VERSION ""

NS_ :

BS_:

BU_: Vector__XXX

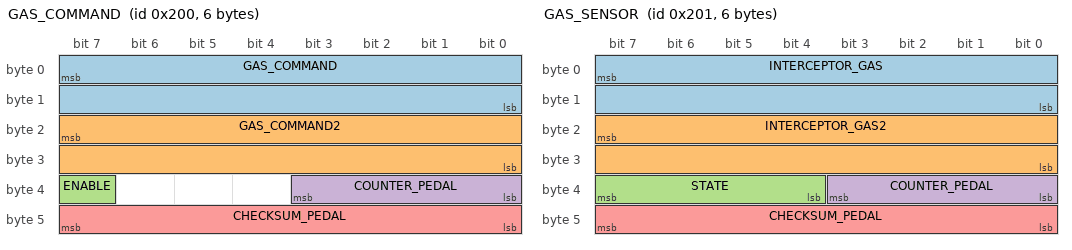
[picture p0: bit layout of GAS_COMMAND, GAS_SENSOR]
BO_ 512 GAS_COMMAND: 6 Vector__XXX
SG_ GAS_COMMAND : 7|16@0+ (0.253984064,-83.3) [0|1] "" Vector__XXX
SG_ GAS_COMMAND2 : 23|16@0+ (0.126992032,-83.3) [0|1] "" Vector__XXX
SG_ ENABLE : 39|1@0+ (1,0) [0|1] "" Vector__XXX
SG_ COUNTER_PEDAL : 35|4@0+ (1,0) [0|15] "" Vector__XXX
SG_ CHECKSUM_PEDAL : 47|8@0+ (1,0) [0|255] "" Vector__XXX

BO_ 513 GAS_SENSOR: 6 Vector__XXX
SG_ INTERCEPTOR_GAS : 7|16@0+ (1,0) [0|1] "" Vector__XXX
SG_ INTERCEPTOR_GAS2 : 23|16@0+ (1,0) [0|1] "" Vector__XXX
SG_ STATE : 39|4@0+ (1,0) [0|15] "" Vector__XXX
SG_ COUNTER_PEDAL : 35|4@0+ (1,0) [0|15] "" Vector__XXX
SG_ CHECKSUM_PEDAL : 47|8@0+ (1,0) [0|255] "" Vector__XXX

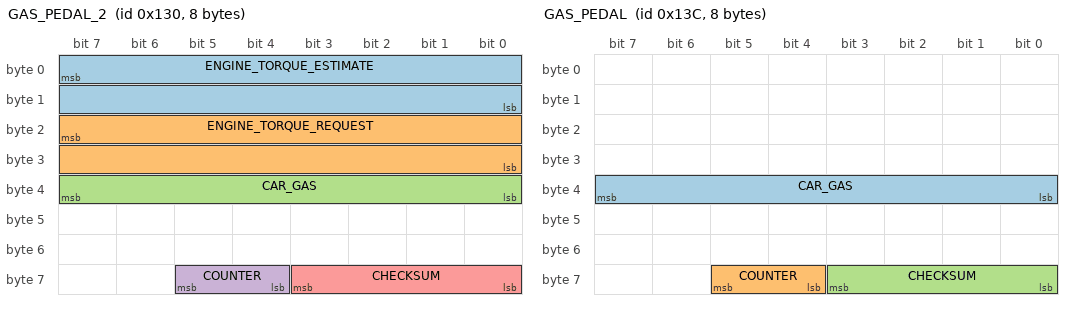
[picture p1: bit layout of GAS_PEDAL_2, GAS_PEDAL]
BO_ 304 GAS_PEDAL_2: 8 Vector__XXX
SG_ ENGINE_TORQUE_ESTIMATE : 7|16@0- (1,0) [-1000|1000] "Nm" Vector__XXX
SG_ ENGINE_TORQUE_REQUEST : 23|16@0- (1,0) [-1000|1000] "Nm" Vector__XXX
SG_ CAR_GAS : 39|8@0+ (1,0) [0|255] "" Vector__XXX
SG_ COUNTER : 61|2@0+ (1,0) [0|3] "" Vector__XXX
SG_ CHECKSUM : 59|4@0+ (1,0) [0|15] "" Vector__XXX

BO_ 316 GAS_PEDAL: 8 Vector__XXX
SG_ CAR_GAS : 39|8@0+ (1,0) [0|255] "" Vector__XXX
SG_ COUNTER : 61|2@0+ (1,0) [0|3] "" Vector__XXX
SG_ CHECKSUM : 59|4@0+ (1,0) [0|15] "" Vector__XXX

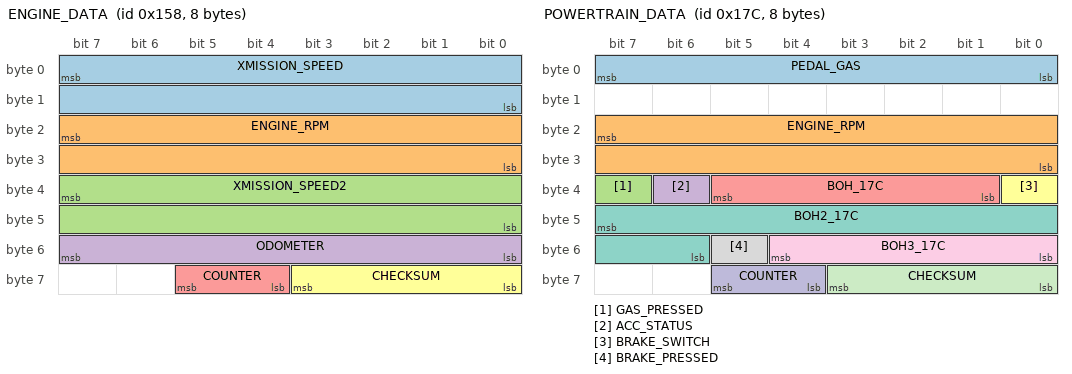
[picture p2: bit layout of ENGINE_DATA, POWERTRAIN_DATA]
BO_ 344 ENGINE_DATA: 8 Vector__XXX
SG_ XMISSION_SPEED : 7|16@0+ (0.01,0) [0|250] "kph" Vector__XXX
SG_ ENGINE_RPM : 23|16@0+ (1,0) [0|15000] "rpm" Vector__XXX
SG_ XMISSION_SPEED2 : 39|16@0+ (0.01,0) [0|250] "kph" Vector__XXX
SG_ ODOMETER : 55|8@0+ (10,0) [0|2550] "m" Vector__XXX
SG_ COUNTER : 61|2@0+ (1,0) [0|3] "" Vector__XXX
SG_ CHECKSUM : 59|4@0+ (1,0) [0|15] "" Vector__XXX

BO_ 380 POWERTRAIN_DATA: 8 Vector__XXX
SG_ PEDAL_GAS : 7|8@0+ (1,0) [0|255] "" Vector__XXX
SG_ ENGINE_RPM : 23|16@0+ (1,0) [0|15000] "rpm" Vector__XXX
SG_ GAS_PRESSED : 39|1@0+ (1,0) [0|1] "" Vector__XXX
SG_ ACC_STATUS : 38|1@0+ (1,0) [0|1] "" Vector__XXX
SG_ BOH_17C : 37|5@0+ (1,0) [0|1] "" Vector__XXX
SG_ BRAKE_SWITCH : 32|1@0+ (1,0) [0|1] "" Vector__XXX
SG_ BOH2_17C : 47|10@0+ (1,0) [0|1] "" Vector__XXX
SG_ BRAKE_PRESSED : 53|1@0+ (1,0) [0|1] "" Vector__XXX
SG_ BOH3_17C : 52|5@0+ (1,0) [0|1] "" Vector__XXX
SG_ COUNTER : 61|2@0+ (1,0) [0|3] "" Vector__XXX
SG_ CHECKSUM : 59|4@0+ (1,0) [0|15] "" Vector__XXX

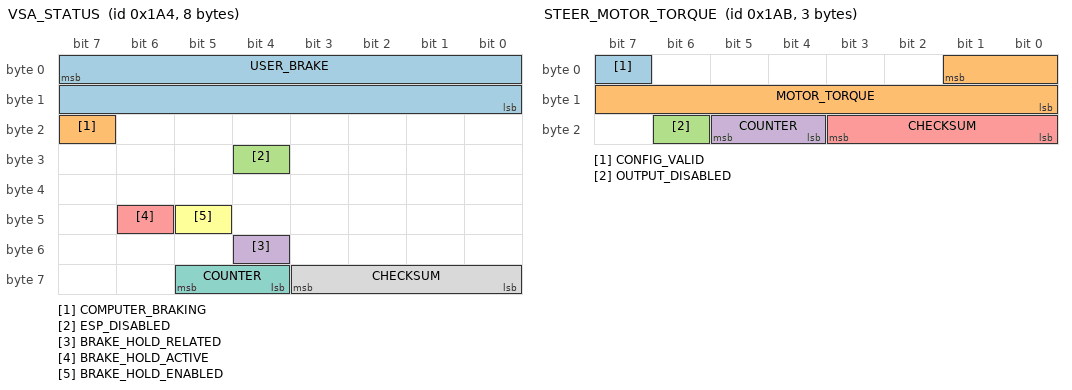
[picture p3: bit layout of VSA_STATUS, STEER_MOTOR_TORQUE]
BO_ 420 VSA_STATUS: 8 Vector__XXX
SG_ USER_BRAKE : 7|16@0+ (0.015625,-1.609375) [0|1000] "" Vector__XXX
SG_ COMPUTER_BRAKING : 23|1@0+ (1,0) [0|1] "" Vector__XXX
SG_ ESP_DISABLED : 28|1@0+ (1,0) [0|1] "" Vector__XXX
SG_ BRAKE_HOLD_RELATED : 52|1@0+ (1,0) [0|1] "" Vector__XXX
SG_ BRAKE_HOLD_ACTIVE : 46|1@0+ (1,0) [0|1] "" Vector__XXX
SG_ BRAKE_HOLD_ENABLED : 45|1@0+ (1,0) [0|1] "" Vector__XXX
SG_ COUNTER : 61|2@0+ (1,0) [0|3] "" Vector__XXX
SG_ CHECKSUM : 59|4@0+ (1,0) [0|15] "" Vector__XXX

BO_ 427 STEER_MOTOR_TORQUE: 3 Vector__XXX
SG_ CONFIG_VALID : 7|1@0+ (1,0) [0|1] "" Vector__XXX
SG_ MOTOR_TORQUE : 1|10@0+ (1,0) [0|256] "" Vector__XXX
SG_ OUTPUT_DISABLED : 22|1@0+ (1,0) [0|1] "" Vector__XXX
SG_ COUNTER : 21|2@0+ (1,0) [0|3] "" Vector__XXX
SG_ CHECKSUM : 19|4@0+ (1,0) [0|15] "" Vector__XXX

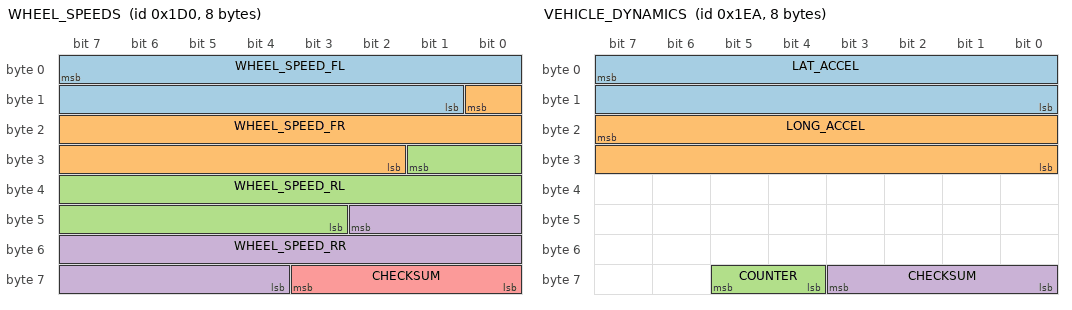
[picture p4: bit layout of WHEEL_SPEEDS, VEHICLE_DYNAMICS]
BO_ 464 WHEEL_SPEEDS: 8 Vector__XXX
SG_ WHEEL_SPEED_FL : 7|15@0+ (0.01,0) [0|250] "kph" Vector__XXX
SG_ WHEEL_SPEED_FR : 8|15@0+ (0.01,0) [0|250] "kph" Vector__XXX
SG_ WHEEL_SPEED_RL : 25|15@0+ (0.01,0) [0|250] "kph" Vector__XXX
SG_ WHEEL_SPEED_RR : 42|15@0+ (0.01,0) [0|250] "kph" Vector__XXX
SG_ CHECKSUM : 59|4@0+ (1,0) [0|3] "" Vector__XXX

BO_ 490 VEHICLE_DYNAMICS: 8 Vector__XXX
SG_ LAT_ACCEL : 7|16@0- (0.0015,0) [-20|20] "m/s2" Vector__XXX
SG_ LONG_ACCEL : 23|16@0- (0.0015,0) [-20|20] "m/s2" Vector__XXX
SG_ COUNTER : 61|2@0+ (1,0) [0|3] "" Vector__XXX
SG_ CHECKSUM : 59|4@0+ (1,0) [0|3] "" Vector__XXX

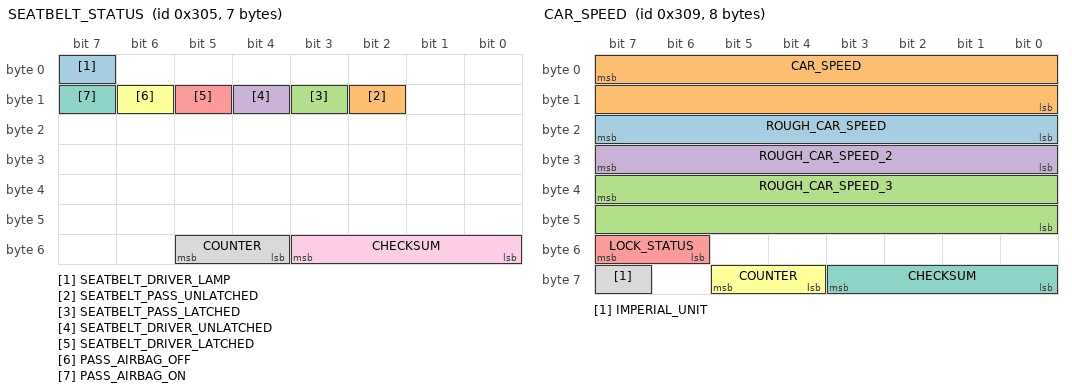
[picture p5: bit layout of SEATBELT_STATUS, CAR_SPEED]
BO_ 773 SEATBELT_STATUS: 7 Vector__XXX
SG_ SEATBELT_DRIVER_LAMP : 7|1@0+ (1,0) [0|1] "" Vector__XXX
SG_ SEATBELT_PASS_UNLATCHED : 10|1@0+ (1,0) [0|1] "" Vector__XXX
SG_ SEATBELT_PASS_LATCHED : 11|1@0+ (1,0) [0|1] "" Vector__XXX
SG_ SEATBELT_DRIVER_UNLATCHED : 12|1@0+ (1,0) [0|1] "" Vector__XXX
SG_ SEATBELT_DRIVER_LATCHED : 13|1@0+ (1,0) [0|1] "" Vector__XXX
SG_ PASS_AIRBAG_OFF : 14|1@0+ (1,0) [0|1] "" Vector__XXX
SG_ PASS_AIRBAG_ON : 15|1@0+ (1,0) [0|1] "" Vector__XXX
SG_ COUNTER : 53|2@0+ (1,0) [0|3] "" Vector__XXX
SG_ CHECKSUM : 51|4@0+ (1,0) [0|3] "" Vector__XXX

BO_ 777 CAR_SPEED: 8 Vector__XXX
SG_ ROUGH_CAR_SPEED : 23|8@0+ (1,0) [0|255] "mph" Vector__XXX
SG_ CAR_SPEED : 7|16@0+ (0.01,0) [0|655.35] "kph" Vector__XXX
SG_ ROUGH_CAR_SPEED_3 : 39|16@0+ (0.01,0) [0|655.35] "kph" Vector__XXX
SG_ ROUGH_CAR_SPEED_2 : 31|8@0+ (1,0) [0|255] "mph" Vector__XXX
SG_ LOCK_STATUS : 55|2@0+ (1,0) [0|3] "" Vector__XXX
SG_ COUNTER : 61|2@0+ (1,0) [0|3] "" Vector__XXX
SG_ CHECKSUM : 59|4@0+ (1,0) [0|15] "" Vector__XXX
SG_ IMPERIAL_UNIT : 63|1@0+ (1,0) [0|1] "" Vector__XXX

BO_ 780 ACC_HUD: 8 Vector__XXX
SG_ PCM_SPEED : 7|16@0+ (0.01,0) [0|250] "kph" Vector__XXX
SG_ PCM_GAS : 23|8@0+ (1,0) [0|127] "" Vector__XXX
SG_ CRUISE_SPEED : 31|8@0+ (1,0) [0|255] "kph" Vector__XXX
SG_ DTC_MODE : 39|1@0+ (1,0) [0|1] "" Vector__XXX
SG_ BOH : 38|1@0+ (1,0) [0|1] "" Vector__XXX
SG_ ACC_PROBLEM : 37|1@0+ (1,0) [0|1] "" Vector__XXX
SG_ FCM_OFF : 35|1@0+ (1,0) [0|1] "" Vector__XXX
SG_ FCM_OFF_2 : 36|1@0+ (1,0) [0|1] "" Vector__XXX
SG_ FCM_PROBLEM : 34|1@0+ (1,0) [0|1] "" Vector__XXX
SG_ RADAR_OBSTRUCTED : 33|1@0+ (1,0) [0|1] "" Vector__XXX
SG_ ENABLE_MINI_CAR : 32|1@0+ (1,0) [0|1] "" Vector__XXX
SG_ HUD_DISTANCE : 47|2@0+ (1,0) [0|3] "" Vector__XXX
SG_ HUD_LEAD : 45|2@0+ (1,0) [0|3] "" Vector__XXX
SG_ BOH_3 : 43|1@0+ (1,0) [0|1] "" Vector__XXX
SG_ BOH_4 : 42|1@0+ (1,0) [0|1] "" Vector__XXX
SG_ BOH_5 : 41|1@0+ (1,0) [0|1] "" Vector__XXX
SG_ CRUISE_CONTROL_LABEL : 40|1@0+ (1,0) [0|1] "" Vector__XXX
SG_ SET_ME_X01_2 : 55|1@0+ (1,0) [0|1] "" Vector__XXX
SG_ IMPERIAL_UNIT : 54|1@0+ (1,0) [0|1] "" Vector__XXX
SG_ ACC_ON : 52|1@0+ (1,0) [0|1] "" Vector__XXX
SG_ CHIME : 51|3@0+ (1,0) [0|1] "" Vector__XXX
SG_ SET_ME_X01 : 48|1@0+ (1,0) [0|1] "" Vector__XXX
SG_ ICONS : 63|2@0+ (1,0) [0|1] "" Vector__XXX
SG_ COUNTER : 61|2@0+ (1,0) [0|3] "" Vector__XXX
SG_ CHECKSUM : 59|4@0+ (1,0) [0|3] "" Vector__XXX

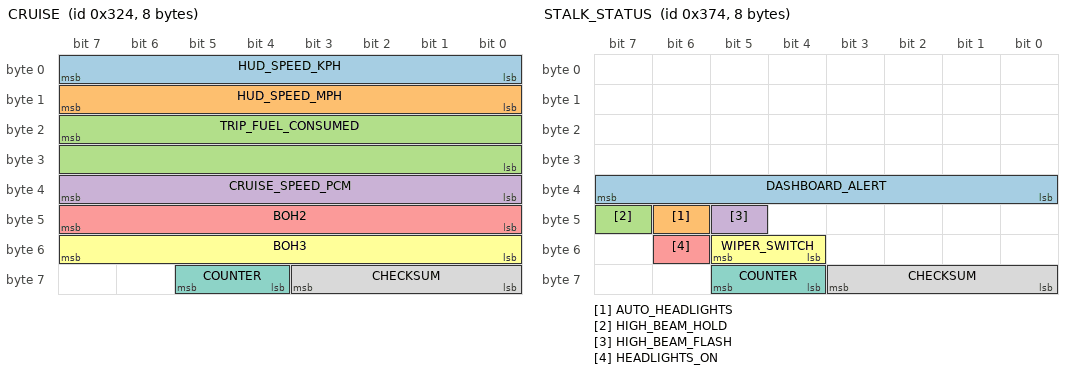
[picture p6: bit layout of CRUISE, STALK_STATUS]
BO_ 804 CRUISE: 8 Vector__XXX
SG_ HUD_SPEED_KPH : 7|8@0+ (1,0) [0|255] "kph" Vector__XXX
SG_ HUD_SPEED_MPH : 15|8@0+ (1,0) [0|255] "mph" Vector__XXX
SG_ TRIP_FUEL_CONSUMED : 23|16@0+ (1,0) [0|255] "" Vector__XXX
SG_ CRUISE_SPEED_PCM : 39|8@0+ (1,0) [0|255] "" Vector__XXX
SG_ BOH2 : 47|8@0- (1,0) [0|127] "" Vector__XXX
SG_ BOH3 : 55|8@0+ (1,0) [0|255] "" Vector__XXX
SG_ COUNTER : 61|2@0+ (1,0) [0|3] "" Vector__XXX
SG_ CHECKSUM : 59|4@0+ (1,0) [0|15] "" Vector__XXX

BO_ 884 STALK_STATUS: 8 Vector__XXX
SG_ DASHBOARD_ALERT : 39|8@0+ (1,0) [0|255] "" Vector__XXX
SG_ AUTO_HEADLIGHTS : 46|1@0+ (1,0) [0|1] "" Vector__XXX
SG_ HIGH_BEAM_HOLD : 47|1@0+ (1,0) [0|1] "" Vector__XXX
SG_ HIGH_BEAM_FLASH : 45|1@0+ (1,0) [0|1] "" Vector__XXX
SG_ HEADLIGHTS_ON : 54|1@0+ (1,0) [0|1] "" Vector__XXX
SG_ WIPER_SWITCH : 53|2@0+ (1,0) [0|3] "" Vector__XXX
SG_ COUNTER : 61|2@0+ (1,0) [0|3] "" Vector__XXX
SG_ CHECKSUM : 59|4@0+ (1,0) [0|15] "" Vector__XXX

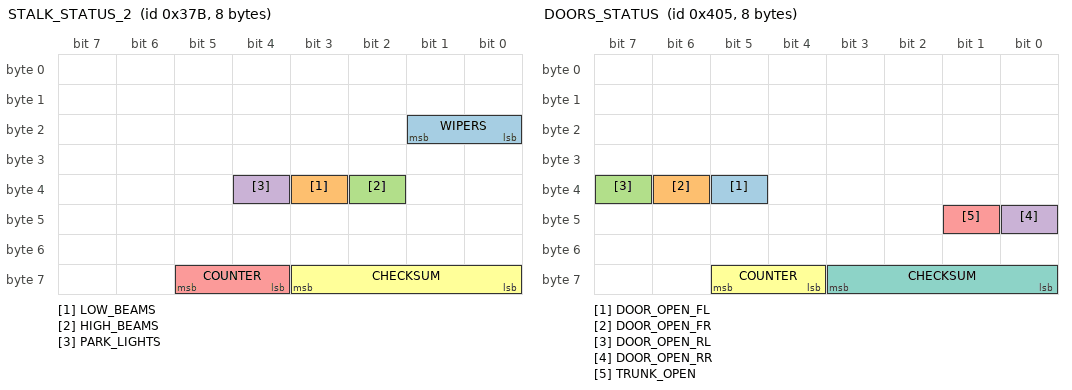
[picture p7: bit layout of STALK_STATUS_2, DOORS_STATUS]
BO_ 891 STALK_STATUS_2: 8 Vector__XXX
SG_ WIPERS : 17|2@0+ (1,0) [0|3] "" Vector__XXX
SG_ LOW_BEAMS : 35|1@0+ (1,0) [0|1] "" Vector__XXX
SG_ HIGH_BEAMS : 34|1@0+ (1,0) [0|1] "" Vector__XXX
SG_ PARK_LIGHTS : 36|1@0+ (1,0) [0|1] "" Vector__XXX
SG_ COUNTER : 61|2@0+ (1,0) [0|3] "" Vector__XXX
SG_ CHECKSUM : 59|4@0+ (1,0) [0|15] "" Vector__XXX

BO_ 1029 DOORS_STATUS: 8 Vector__XXX
SG_ DOOR_OPEN_FL : 37|1@0+ (1,0) [0|1] "" Vector__XXX
SG_ DOOR_OPEN_FR : 38|1@0+ (1,0) [0|1] "" Vector__XXX
SG_ DOOR_OPEN_RL : 39|1@0+ (1,0) [0|1] "" Vector__XXX
SG_ DOOR_OPEN_RR : 40|1@0+ (1,0) [0|1] "" Vector__XXX
SG_ TRUNK_OPEN : 41|1@0+ (1,0) [0|1] "" Vector__XXX
SG_ COUNTER : 61|2@0+ (1,0) [0|3] "" Vector__XXX
SG_ CHECKSUM : 59|4@0+ (1,0) [0|15] "" Vector__XXX

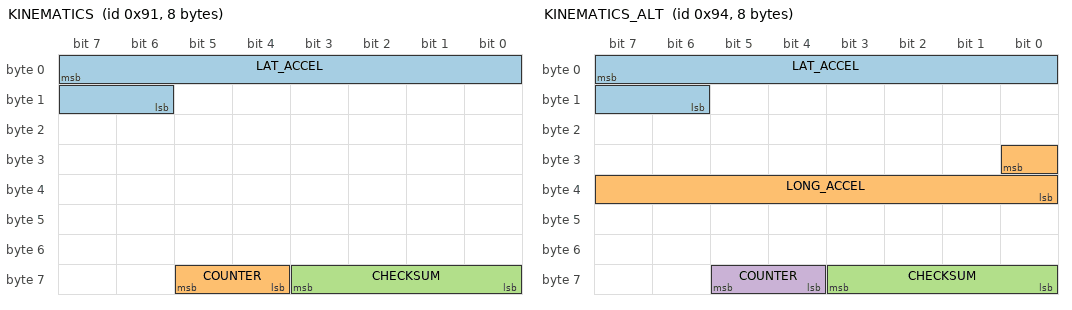
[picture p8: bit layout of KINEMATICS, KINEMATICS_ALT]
BO_ 145 KINEMATICS: 8 Vector__XXX
SG_ LAT_ACCEL : 7|10@0+ (0.02,-512) [-20|-491.54] "m/s2" Vector__XXX
SG_ COUNTER : 61|2@0+ (1,0) [0|3] "" Vector__XXX
SG_ CHECKSUM : 59|4@0+ (1,0) [0|3] "" Vector__XXX

BO_ 148 KINEMATICS_ALT: 8 Vector__XXX
SG_ LAT_ACCEL : 7|10@0+ (0.02,-512) [-20|-491.54] "m/s2" Vector__XXX
SG_ LONG_ACCEL : 24|9@0- (-0.02,0) [-5.1|5.12] "m/s2" Vector__XXX
SG_ CHECKSUM : 59|4@0+ (1,0) [0|3] "" Vector__XXX
SG_ COUNTER : 61|2@0+ (1,0) [0|3] "" Vector__XXX

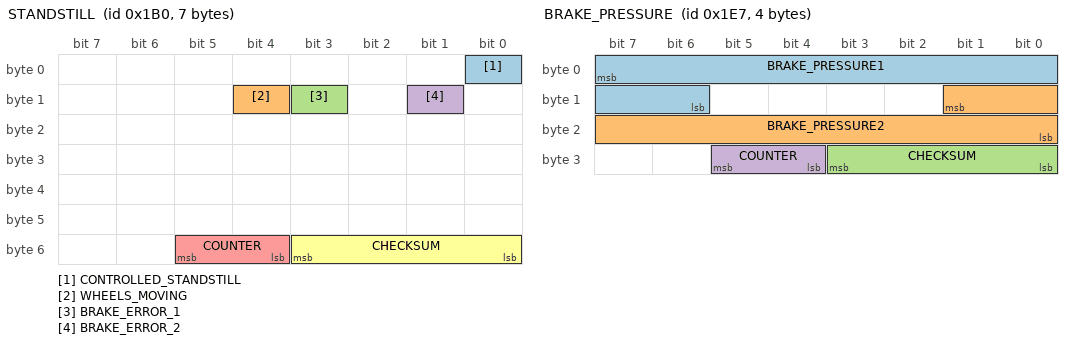
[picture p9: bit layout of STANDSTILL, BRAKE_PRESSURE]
BO_ 432 STANDSTILL: 7 Vector__XXX
SG_ CONTROLLED_STANDSTILL : 0|1@0+ (1,0) [0|1] "" Vector__XXX
SG_ WHEELS_MOVING : 12|1@0+ (1,0) [0|1] "" Vector__XXX
SG_ BRAKE_ERROR_1 : 11|1@0+ (1,0) [0|1] "" Vector__XXX
SG_ BRAKE_ERROR_2 : 9|1@0+ (1,0) [0|1] "" Vector__XXX
SG_ COUNTER : 53|2@0+ (1,0) [0|3] "" Vector__XXX
SG_ CHECKSUM : 51|4@0+ (1,0) [0|3] "" Vector__XXX

BO_ 487 BRAKE_PRESSURE: 4 Vector__XXX
SG_ BRAKE_PRESSURE1 : 7|10@0+ (0.015625,-103) [0|-87.015625] "" Vector__XXX
SG_ BRAKE_PRESSURE2 : 9|10@0+ (0.015625,-103) [0|-87.015625] "" Vector__XXX
SG_ CHECKSUM : 27|4@0+ (1,0) [0|15] "" Vector__XXX
SG_ COUNTER : 29|2@0+ (1,0) [0|3] "" Vector__XXX

BO_ 506 BRAKE_COMMAND: 8 Vector__XXX
SG_ COMPUTER_BRAKE : 7|10@0+ (1,0) [0|1] "" Vector__XXX
SG_ BRAKE_PUMP_REQUEST : 8|1@0+ (1,0) [0|1] "" Vector__XXX
SG_ BRAKE_PUMP_REQUEST_ALT : 11|1@0+ (1,0) [0|1] "" Vector__XXX
SG_ SET_ME_X00 : 23|3@0+ (1,0) [0|1] "" Vector__XXX
SG_ CRUISE_OVERRIDE : 20|1@0+ (1,0) [0|1] "" Vector__XXX
SG_ SET_ME_X00_2 : 19|1@0+ (1,0) [0|1] "" Vector__XXX
SG_ CRUISE_FAULT_CMD : 18|1@0+ (1,0) [0|1] "" Vector__XXX
SG_ CRUISE_CANCEL_CMD : 17|1@0+ (1,0) [0|1] "" Vector__XXX
SG_ COMPUTER_BRAKE_REQUEST : 16|1@0+ (1,0) [0|1] "" Vector__XXX
SG_ SET_ME_1 : 31|1@0+ (1,0) [0|1] "" Vector__XXX
SG_ AEB_REQ_1 : 29|1@0+ (1,0) [0|1] "" Vector__XXX
SG_ AEB_REQ_2 : 26|3@0+ (1,0) [0|7] "" Vector__XXX
SG_ BRAKE_LIGHTS : 39|1@0+ (1,0) [0|1] "" Vector__XXX
SG_ CRUISE_STATES : 38|7@0+ (1,0) [0|1] "" Vector__XXX
SG_ CHIME : 47|3@0+ (1,0) [0|7] "" Vector__XXX
SG_ SET_ME_X00_3 : 44|1@0+ (1,0) [0|1] "" Vector__XXX
SG_ FCW : 43|2@0+ (1,0) [0|3] "" Vector__XXX
SG_ AEB_STATUS : 41|2@0+ (1,0) [0|3] "" Vector__XXX
SG_ COMPUTER_BRAKE_ALT : 55|10@0+ (1,0) [0|1023] "" Vector__XXX
SG_ COUNTER : 61|2@0+ (1,0) [0|3] "" Vector__XXX
SG_ CHECKSUM : 59|4@0+ (1,0) [0|15] "" Vector__XXX

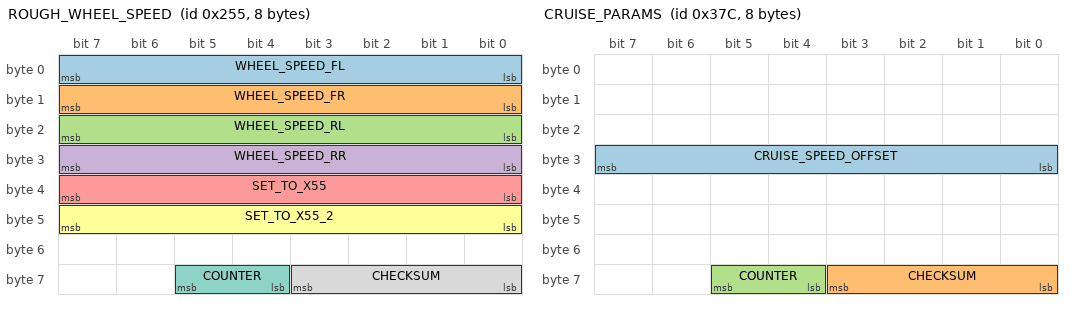
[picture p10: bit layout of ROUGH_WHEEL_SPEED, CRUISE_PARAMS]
BO_ 597 ROUGH_WHEEL_SPEED: 8 Vector__XXX
SG_ WHEEL_SPEED_FL : 7|8@0+ (1,0) [0|255] "mph" Vector__XXX
SG_ WHEEL_SPEED_FR : 15|8@0+ (1,0) [0|255] "mph" Vector__XXX
SG_ WHEEL_SPEED_RL : 23|8@0+ (1,0) [0|255] "mph" Vector__XXX
SG_ WHEEL_SPEED_RR : 31|8@0+ (1,0) [0|255] "mph" Vector__XXX
SG_ SET_TO_X55 : 39|8@0+ (1,0) [0|255] "" Vector__XXX
SG_ SET_TO_X55_2 : 47|8@0+ (1,0) [0|255] "" Vector__XXX
SG_ COUNTER : 61|2@0+ (1,0) [0|3] "" Vector__XXX
SG_ CHECKSUM : 59|4@0+ (1,0) [0|15] "" Vector__XXX

BO_ 829 LKAS_HUD: 5 Vector__XXX
SG_ CAM_TEMP_HIGH : 7|1@0+ (1,0) [0|1] "" Vector__XXX
SG_ SET_ME_X41 : 6|7@0+ (1,0) [0|127] "" Vector__XXX
SG_ BOH : 6|7@0+ (1,0) [0|127] "" Vector__XXX
SG_ DASHED_LANES : 14|1@0+ (1,0) [0|1] "" Vector__XXX
SG_ DTC : 13|1@0+ (1,0) [0|1] "" Vector__XXX
SG_ LKAS_PROBLEM : 12|1@0+ (1,0) [0|1] "" Vector__XXX
SG_ LKAS_OFF : 11|1@0+ (1,0) [0|1] "" Vector__XXX
SG_ SOLID_LANES : 10|1@0+ (1,0) [0|1] "" Vector__XXX
SG_ LDW_RIGHT : 9|1@0+ (1,0) [0|1] "" Vector__XXX
SG_ STEERING_REQUIRED : 8|1@0+ (1,0) [0|1] "" Vector__XXX
SG_ BOH_2 : 23|2@0+ (1,0) [0|3] "" Vector__XXX
SG_ LDW_PROBLEM : 21|1@0+ (1,0) [0|1] "" Vector__XXX
SG_ BEEP : 17|2@0+ (1,0) [0|1] "" Vector__XXX
SG_ LDW_ON : 28|1@0+ (1,0) [0|1] "" Vector__XXX
SG_ LDW_OFF : 27|1@0+ (1,0) [0|1] "" Vector__XXX
SG_ CLEAN_WINDSHIELD : 26|1@0+ (1,0) [0|1] "" Vector__XXX
SG_ SET_ME_X48 : 31|8@0+ (1,0) [0|255] "" Vector__XXX
SG_ COUNTER : 37|2@0+ (1,0) [0|3] "" Vector__XXX
SG_ CHECKSUM : 35|4@0+ (1,0) [0|15] "" Vector__XXX

BO_ 892 CRUISE_PARAMS: 8 Vector__XXX
SG_ CRUISE_SPEED_OFFSET : 31|8@0- (0.1,0) [-12.8|12.7] "kph" Vector__XXX
SG_ CHECKSUM : 59|4@0+ (1,0) [0|3] "" Vector__XXX
SG_ COUNTER : 61|2@0+ (1,0) [0|3] "" Vector__XXX

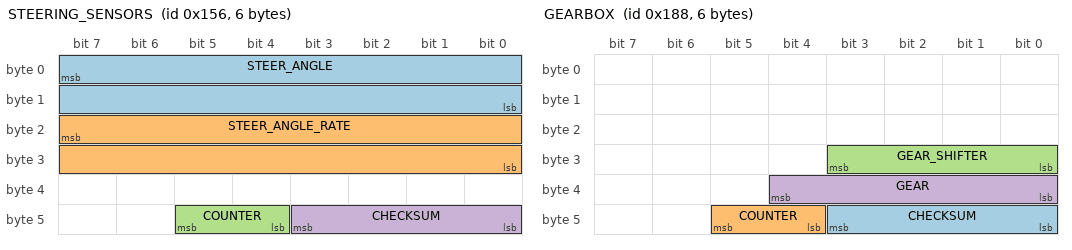
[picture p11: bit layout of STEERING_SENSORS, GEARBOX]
BO_ 342 STEERING_SENSORS: 6 Vector__XXX
SG_ STEER_ANGLE : 7|16@0- (-0.1,0) [-500|500] "deg" Vector__XXX
SG_ STEER_ANGLE_RATE : 23|16@0- (-1,0) [-3000|3000] "deg/s" Vector__XXX
SG_ COUNTER : 45|2@0+ (1,0) [0|3] "" Vector__XXX
SG_ CHECKSUM : 43|4@0+ (1,0) [0|15] "" Vector__XXX

BO_ 392 GEARBOX: 6 Vector__XXX
SG_ CHECKSUM : 43|4@0+ (1,0) [0|15] "" Vector__XXX
SG_ COUNTER : 45|2@0+ (1,0) [0|3] "" Vector__XXX
SG_ GEAR_SHIFTER : 27|4@0+ (1,0) [0|15] "" Vector__XXX
SG_ GEAR : 36|5@0+ (1,0) [0|31] "" Vector__XXX

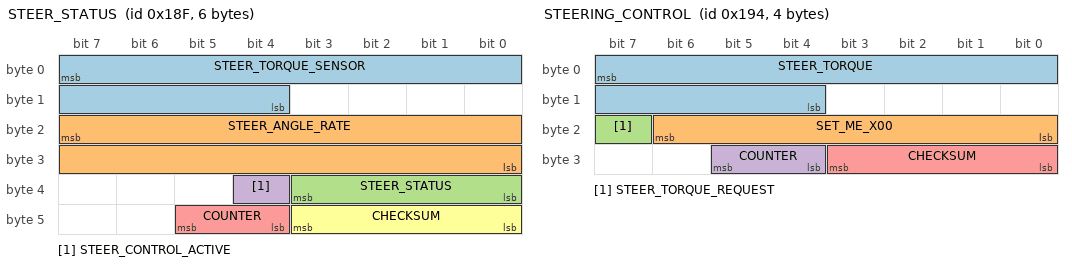
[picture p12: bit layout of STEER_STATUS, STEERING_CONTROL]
BO_ 399 STEER_STATUS: 6 Vector__XXX
SG_ STEER_TORQUE_SENSOR : 7|12@0- (-1,0) [-2047|2047.5] "tbd" Vector__XXX
SG_ STEER_ANGLE_RATE : 23|16@0- (-0.1,0) [-3276.7|3276.8] "deg/s" Vector__XXX
SG_ STEER_STATUS : 35|4@0+ (1,0) [0|15] "" Vector__XXX
SG_ STEER_CONTROL_ACTIVE : 36|1@0+ (1,0) [0|1] "" Vector__XXX
SG_ COUNTER : 45|2@0+ (1,0) [0|3] "" Vector__XXX
SG_ CHECKSUM : 43|4@0+ (1,0) [0|15] "" Vector__XXX

BO_ 404 STEERING_CONTROL: 4 Vector__XXX
SG_ STEER_TORQUE : 7|12@0- (1,0) [-768|768] "" Vector__XXX
SG_ SET_ME_X00 : 22|7@0+ (1,0) [0|127] "" Vector__XXX
SG_ STEER_TORQUE_REQUEST : 23|1@0+ (1,0) [0|1] "" Vector__XXX
SG_ COUNTER : 29|2@0+ (1,0) [0|3] "" Vector__XXX
SG_ CHECKSUM : 27|4@0+ (1,0) [0|3] "" Vector__XXX

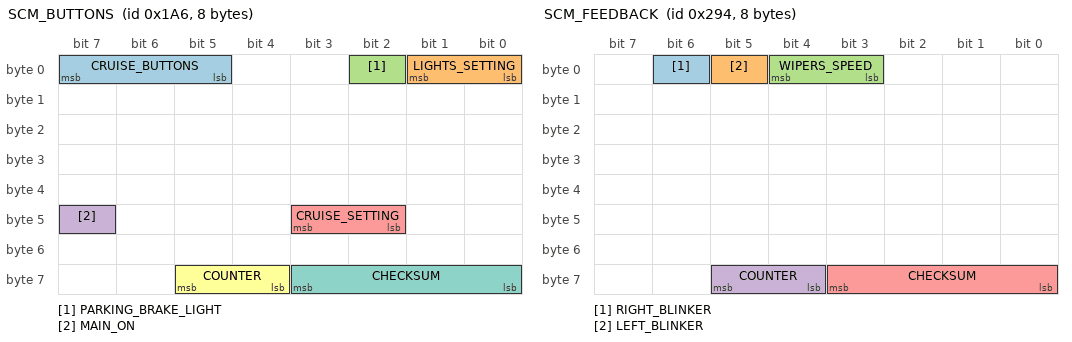
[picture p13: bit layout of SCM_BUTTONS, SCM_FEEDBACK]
BO_ 422 SCM_BUTTONS: 8 Vector__XXX
SG_ CRUISE_BUTTONS : 7|3@0+ (1,0) [0|7] "" Vector__XXX
SG_ LIGHTS_SETTING : 1|2@0+ (1,0) [0|3] "" Vector__XXX
SG_ PARKING_BRAKE_LIGHT : 2|1@0+ (1,0) [0|1] "" Vector__XXX
SG_ MAIN_ON : 47|1@0+ (1,0) [0|1] "" Vector__XXX
SG_ CRUISE_SETTING : 43|2@0+ (1,0) [0|3] "" Vector__XXX
SG_ COUNTER : 61|2@0+ (1,0) [0|3] "" Vector__XXX
SG_ CHECKSUM : 59|4@0+ (1,0) [0|15] "" Vector__XXX

BO_ 660 SCM_FEEDBACK: 8 Vector__XXX
SG_ RIGHT_BLINKER : 6|1@0+ (1,0) [0|1] "" Vector__XXX
SG_ LEFT_BLINKER : 5|1@0+ (1,0) [0|1] "" Vector__XXX
SG_ WIPERS_SPEED : 4|2@0+ (1,0) [0|3] "" Vector__XXX
SG_ COUNTER : 61|2@0+ (1,0) [0|3] "" Vector__XXX
SG_ CHECKSUM : 59|4@0+ (1,0) [0|15] "" Vector__XXX

CM_ SG_ 420 BRAKE_HOLD_RELATED "On when Brake Hold engaged";
CM_ SG_ 490 LONG_ACCEL "wheel speed derivative, noisy and zero snapping";
CM_ SG_ 773 PASS_AIRBAG_OFF "Might just be indicator light";
CM_ SG_ 773 PASS_AIRBAG_ON "Might just be indicator light";
CM_ SG_ 780 PCM_SPEED "Used by Nidec";
CM_ SG_ 780 PCM_GAS "Used by Nidec";
CM_ SG_ 780 CRUISE_SPEED "255 = no speed";
CM_ SG_ 804 CRUISE_SPEED_PCM "255 = no speed";
CM_ SG_ 506 BRAKE_PUMP_REQUEST_ALT "Used by dual-can Nidec";
CM_ SG_ 506 AEB_REQ_1 "set for duration of suspected AEB event";
CM_ SG_ 506 COMPUTER_BRAKE_ALT "Used by dual-can Nidec";
CM_ SG_ 829 BEEP "beeps are pleasant, chimes are for warnngs etc...";
CM_ SG_ 422 PARKING_BRAKE_LIGHT "Believe this is just the dash light for the parking break";

BA_DEF_  "BusType" STRING ;
BA_DEF_ SG_  "GenSigStartValue" FLOAT -3.4E+038 3.4E+038;

BA_DEF_DEF_  "BusType" "CAN";
BA_DEF_DEF_  "GenSigStartValue" 0;

BA_ "GenSigStartValue" SG_ 145 LAT_ACCEL -491.54;
BA_ "GenSigStartValue" SG_ 148 LAT_ACCEL -491.54;
BA_ "GenSigStartValue" SG_ 487 BRAKE_PRESSURE1 -87.015625;
BA_ "GenSigStartValue" SG_ 487 BRAKE_PRESSURE2 -87.015625;
VAL_ 513 STATE 5 "FAULT_TIMEOUT" 4 "FAULT_STARTUP" 3 "FAULT_SCE" 2 "FAULT_SEND" 1 "FAULT_BAD_CHECKSUM" 0 "NO_FAULT";
VAL_ 780 CRUISE_SPEED 255 "no_speed" 252 "stopped";
VAL_ 780 HUD_LEAD 3 "acc_off" 2 "solid_car" 1 "dashed_car" 0 "no_car";
VAL_ 884 DASHBOARD_ALERT 0 "none" 51 "acc_problem" 55 "cmbs_problem" 75 "key_not_detected" 79 "fasten_seatbelt" 111 "lkas_problem" 131 "brake_system_problem" 132 "brake_hold_problem" 139 "tbd" 161 "door_open";
VAL_ 891 WIPERS 4 "High" 2 "Low" 0 "Off";
VAL_ 506 CHIME 4 "double_chime" 3 "single_chime" 2 "continuous_chime" 1 "repeating_chime" 0 "no_chime";
VAL_ 506 FCW 3 "fcw" 2 "fcw" 1 "fcw" 0 "no_fcw";
VAL_ 506 AEB_STATUS 3 "aeb_prepare" 2 "aeb_ready" 1 "aeb_braking" 0 "no_aeb";
VAL_ 829 BEEP 3 "single_beep" 2 "triple_beep" 1 "repeated_beep" 0 "no_beep";
VAL_ 392 GEAR_SHIFTER 0 "S" 1 "P" 2 "R" 4 "N" 8 "D";
VAL_ 392 GEAR 26 "S" 4 "D" 3 "N" 2 "R" 1 "P";
VAL_ 399 STEER_STATUS 6 "tmp_fault" 5 "fault_1" 4 "no_torque_alert_2" 3 "low_speed_lockout" 2 "no_torque_alert_1" 0 "normal";
VAL_ 422 CRUISE_BUTTONS 7 "tbd" 6 "tbd" 5 "tbd" 4 "accel_res" 3 "decel_set" 2 "cancel" 1 "main" 0 "none";
